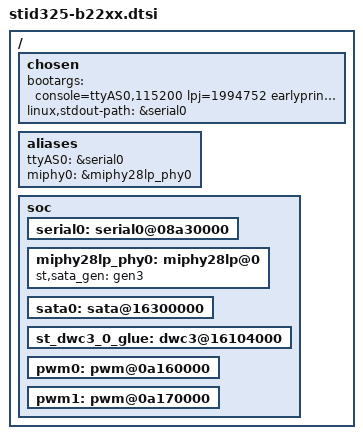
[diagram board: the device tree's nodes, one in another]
/*
 * Copyright (C) 2015 STMicroelectronics (R&D) Limited.
 * Author: Carmelo Amoroso <carmelo.amoroso@st.com>
 * Author: Giuseppe Cavallaro <peppe.cavallaro@st.com>
 * Author: Giuseppe Condorelli <giuseppe.condorelli@st.com>
 *
 * This program is free software; you can redistribute it and/or modify
 * it under the terms of the GNU General Public License version 2 as
 * published by the Free Software Foundation.
 */
#include "stid325.dtsi"

/ {
	chosen {
		bootargs = "console=ttyAS0,115200 lpj=1994752 earlyprintk initcall_debug ignore_loglevel";
		linux,stdout-path = &serial0;
	};

	aliases {
		ttyAS0 = &serial0;
		miphy0 = &miphy28lp_phy0;
	};

	soc {
		serial0: serial0@08a30000 {
			status = "okay";
		};

		miphy28lp_phy0: miphy28lp@0 {
			st,sata_gen = "gen3";
			status = "okay";
		};

		/* Note: external power is needed for SATA device */
		sata0: sata@16300000 {
			status = "okay";
		};

		st_dwc3_0_glue: dwc3@16104000 {
			status = "okay";
		};

		/* Front panel LEDs management */
		pwm0: pwm@0a160000 {
			status = "okay";
		};

		pwm1: pwm@0a170000 {
			status = "okay";
		};
	};
};
